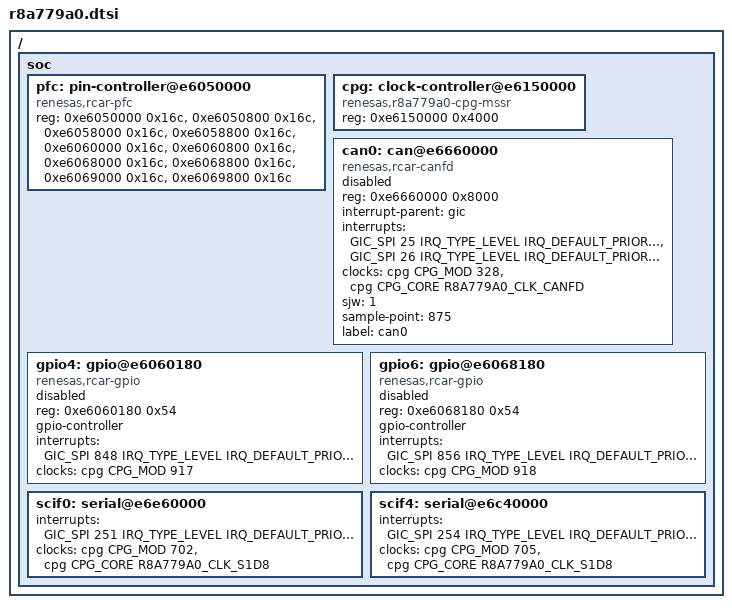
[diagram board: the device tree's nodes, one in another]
/*
 * Copyright (c) 2022 IoT.bzh
 *
 * SPDX-License-Identifier: Apache-2.0
 */

#include <renesas/gen4/rcar_gen4_cr52.dtsi>
#include <zephyr/dt-bindings/clock/r8a779a0_cpg_mssr.h>
#include <zephyr/dt-bindings/gpio/gpio.h>

/ {
    soc {
        pfc: pin-controller@e6050000 {
			compatible = "renesas,rcar-pfc";
			reg = <0xe6050000 0x16c>, <0xe6050800 0x16c>,
			      <0xe6058000 0x16c>, <0xe6058800 0x16c>,
			      <0xe6060000 0x16c>, <0xe6060800 0x16c>,
			      <0xe6068000 0x16c>, <0xe6068800 0x16c>,
			      <0xe6069000 0x16c>, <0xe6069800 0x16c>;
		};

        /* Clock controller
         * Using domain 0 as linux
         * Tried domain 3 unsuccessfully
         */
        cpg: clock-controller@e6150000 {
            compatible = "renesas,r8a779a0-cpg-mssr";
            reg = <0xe6150000 0x4000>;
            #clock-cells = <2>;
        };

        can0: can@e6660000 {
			compatible = "renesas,rcar-canfd";
			reg = <0xe6660000 0x8000>;
			interrupt-parent = <&gic>;
			interrupts = <GIC_SPI 25 IRQ_TYPE_LEVEL
					IRQ_DEFAULT_PRIORITY>,
				     <GIC_SPI 26 IRQ_TYPE_LEVEL
					IRQ_DEFAULT_PRIORITY>;
            clocks = <&cpg CPG_MOD 328>, <&cpg CPG_CORE R8A779A0_CLK_CANFD>; // <&cpg CPG_CORE R8A779A0_CLK_S3D2>; clock always ON.
			sjw = <1>;
			sample-point = <875>;
			status = "disabled";
			label = "can0";
		};

        gpio4: gpio@e6060180 {
            compatible = "renesas,rcar-gpio";
            reg = <0xe6060180 0x54>;
            #gpio-cells = <2>;
            gpio-controller;
            interrupts = <GIC_SPI 848 IRQ_TYPE_LEVEL IRQ_DEFAULT_PRIORITY>;
            clocks = <&cpg CPG_MOD 917>;
            status = "disabled";
        };

        gpio6: gpio@e6068180 {
            compatible = "renesas,rcar-gpio";
            reg = <0xe6068180 0x54>;
            #gpio-cells = <2>;
            gpio-controller;
            interrupts = <GIC_SPI 856 IRQ_TYPE_LEVEL IRQ_DEFAULT_PRIORITY>;
            clocks = <&cpg CPG_MOD 918>;
            status = "disabled";
        };

        scif0: serial@e6e60000 {
            interrupts = <GIC_SPI 251 IRQ_TYPE_LEVEL IRQ_DEFAULT_PRIORITY>;
            clocks = <&cpg CPG_MOD 702>, <&cpg CPG_CORE R8A779A0_CLK_S1D8>;
        };

        scif4: serial@e6c40000 {
            interrupts = <GIC_SPI 254 IRQ_TYPE_LEVEL IRQ_DEFAULT_PRIORITY>;
            clocks = <&cpg CPG_MOD 705>, <&cpg CPG_CORE R8A779A0_CLK_S1D8>;
        };
    };
};
